# STM32L052C6T6 register map
File version: 1.0
STM32L052C6T6,STM32L052C6U6,STM32L052C8T3,STM32L052C8T6,STM32L052C8T7,STM32L052C8U3,STM32L052C8U6,STM32L052C8U7,STM32L052K6T6,STM32L052K6T7,STM32L052K6U6,STM32L052K6U7,STM32L052K8T3,STM32L052K8T6,STM32L052K8T7,STM32L052K8U3,STM32L052K8U6,STM32L052K8U7,STM32L052R6H6,STM32L052R6T6,STM32L052R8H6,STM32L052R8H7,STM32L052R8T6,STM32L052R8T7,STM32L052T6Y6,STM32L052T6Y7,STM32L052T8F3,STM32L052T8F6,STM32L052T8F7,STM32L052T8Y3,STM32L052T8Y6,STM32L052T8Y7,STM32L062C8U6,STM32L062K8T6,STM32L062K8U6,STM32L072CBT6,STM32L072CBU6,STM32L072CBY6,STM32L072CZE3,STM32L072CZE6,STM32L072CZE7,STM32L072CZT3,STM32L072CZT6,STM32L072CZT7,STM32L072CZU3,STM32L072CZU6,STM32L072CZU7,STM32L072CZY3,STM32L072CZY6,STM32L072CZY7,STM32L072KBT6,STM32L072KBT7,STM32L072KBU3,STM32L072KBU6,STM32L072KBU7,STM32L072KZT6,STM32L072KZT7,STM32L072KZU6,STM32L072KZU7,STM32L072RBH3,STM32L072RBH6,STM32L072RBH7,STM32L072RBI3,STM32L072RBI6,STM32L072RBI7,STM32L072RBT3,STM32L072RBT6,STM32L072RBT7,STM32L072RZH3,STM32L072RZH6,STM32L072RZH7,STM32L072RZI3,STM32L072RZI6,STM32L072RZI7,STM32L072RZT3,STM32L072RZT6,STM32L072RZT7,STM32L072V8I6,STM32L072V8T6,STM32L072VBI6,STM32L072VBT6,STM32L072VZI6,STM32L072VZT6,STM32L082CZU3,STM32L082CZU6,STM32L082CZU7,STM32L082CZY3,STM32L082CZY6,STM32L082CZY7,STM32L082KBT6,STM32L082KBU6,STM32L082KZT6,STM32L082KZU6
Registers are 32-bit, access not given, reset 0x0 unless marked. A register's access mark holds for its fields unless they carry their own. Offsets are from the block's base; lines under a group give offsets from that group; [hi:lo] are bit positions; {n}, {i} and the like mark numbered series; 'fields as' and 'values as' point back to an identical list; <NAME> marks a mode.

## Memory map
0x40000000 TIM2
0x40000400 TIM3
0x40001000 TIM6
0x40001400 TIM7
0x40002800 RTC
0x40002800 BKP
0x40002C00 WWDG
0x40003000 IWDG
0x40003800 SPI2
0x40004400 USART2
0x40004800 LPUART1
0x40004C00 USART4
0x40005000 USART5
0x40005400 I2C1
0x40005800 I2C2
0x40005C00 USBFS
0x40006C00 CRS
0x40007000 PWR
0x40007400 DAC12
0x40007800 I2C3
0x40007C00 LPTIM1
0x40010000 COMP
0x40010000 SYSCFG
0x40010400 EXTI
0x40010800 TIM21
0x40011400 TIM22
0x40011C00 FW
0x40012400 ADC1
0x40013000 SPI1
0x40013800 USART1
0x40015800 DBG
0x40020000 DMA1
0x40021000 RCC
0x40022000 FLASH
0x40023000 CRC
0x40024000 TSC
0x40025000 RNG
0x40026000 AES
0x50000000 GPIOA
0x50000400 GPIOB
0x50000800 GPIOC
0x50000C00 GPIOD
0x50001000 GPIOE
0x50001C00 GPIOH

## TIM2
Base 0x40000000
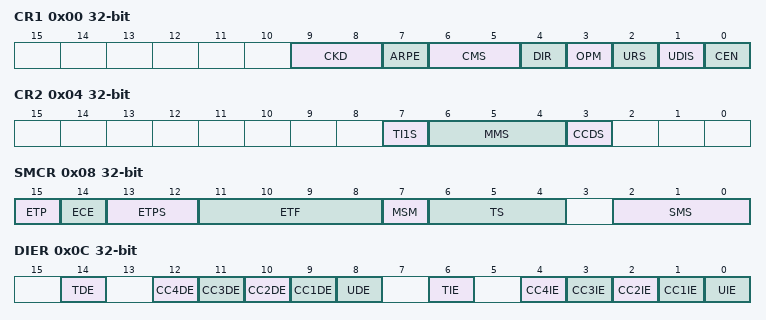
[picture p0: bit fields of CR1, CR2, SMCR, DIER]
0x00 CR1
  [9:8] CKD, [7] ARPE, [6:5] CMS, [4] DIR, [3] OPM, [2] URS, [1] UDIS, [0] CEN
0x04 CR2
  [7] TI1S, [6:4] MMS, [3] CCDS
0x08 SMCR
  [15] ETP, [14] ECE, [13:12] ETPS, [11:8] ETF, [7] MSM, [6:4] TS, [2:0] SMS
0x0C DIER
  [14] TDE, [n+8] CC{n}DE (n=1..4), [8] UDE, [6] TIE, [n] CC{n}IE (n=1..4), [0] UIE
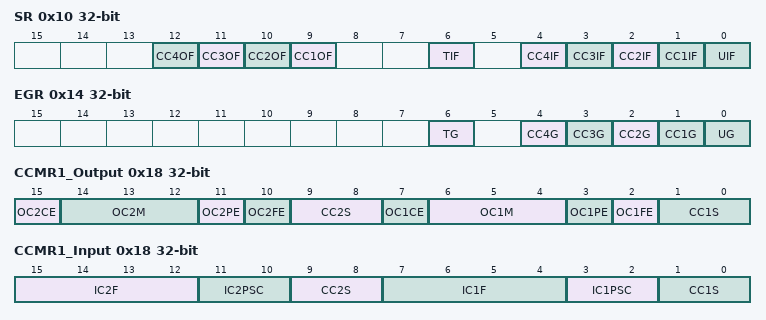
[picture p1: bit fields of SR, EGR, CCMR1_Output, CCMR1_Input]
0x10 SR
  [n+8] CC{n}OF (n=1..4), [6] TIF, [n] CC{n}IF (n=1..4), [0] UIF
0x14 EGR
  [6] TG, [n] CC{n}G (n=1..4), [0] UG
0x18 CCMR1_Output
  [15] OC2CE, [14:12] OC2M, [11] OC2PE, [10] OC2FE, [9:8] CC2S, [7] OC1CE, [6:4] OC1M, [3] OC1PE, [2] OC1FE, [1:0] CC1S
0x18 CCMR1_Input
  [15:12] IC2F, [11:10] IC2PSC, [9:8] CC2S, [7:4] IC1F, [3:2] IC1PSC, [1:0] CC1S
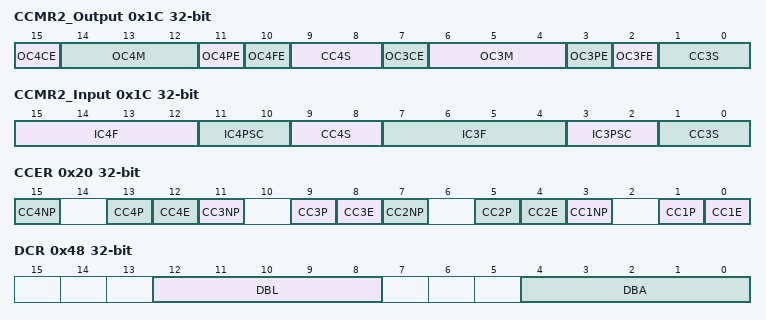
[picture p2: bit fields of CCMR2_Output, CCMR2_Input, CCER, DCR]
0x1C CCMR2_Output
  [15] OC4CE, [14:12] OC4M, [11] OC4PE, [10] OC4FE, [9:8] CC4S, [7] OC3CE, [6:4] OC3M, [3] OC3PE, [2] OC3FE, [1:0] CC3S
0x1C CCMR2_Input
  [15:12] IC4F, [11:10] IC4PSC, [9:8] CC4S, [7:4] IC3F, [3:2] IC3PSC, [1:0] CC3S
0x20 CCER
  [4n-1] CC{n}NP (n=1..4), [4n-3] CC{n}P (n=1..4), [4n-4] CC{n}E (n=1..4)
0x24 CNT
  [15:0] CNT
0x28 PSC
  [15:0] PSC
0x2C ARR
  [15:0] ARR
{0x30+4i} CCR{i} (i=1..4)
  [15:0] CCR{i}
0x48 DCR
  [12:8] DBL, [4:0] DBA
0x4C DMAR
  [15:0] DMAB
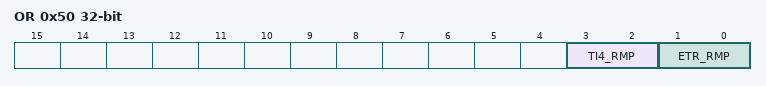
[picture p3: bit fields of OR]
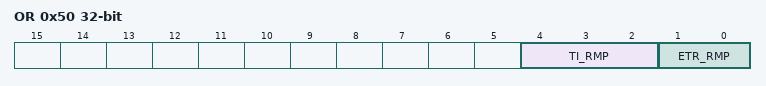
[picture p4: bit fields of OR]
0x50 OR
  [3:2] TI4_RMP, [1:0] ETR_RMP

## TIM3
Base 0x40000400
Registers as TIM2; these are added or differ:
0x50 OR
  [4:2] TI_RMP, [1:0] ETR_RMP

## TIM6
Base 0x40001000
Same registers: TIM7 0x40001400
0x00 CR1
0x04 CR2
0x0C DIER
0x10 SR
0x14 EGR
0x24 CNT
0x28 PSC
0x2C ARR

## RTC
Base 0x40002800
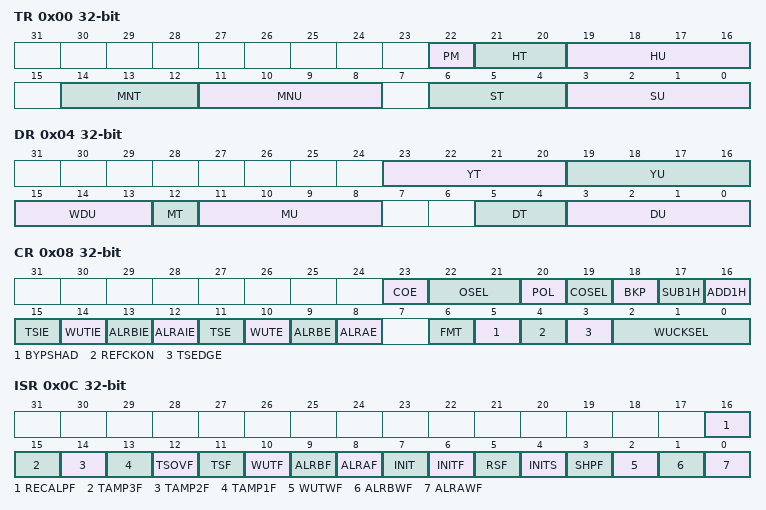
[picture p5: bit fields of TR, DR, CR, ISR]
0x00 TR
  [22] PM, [21:20] HT, [19:16] HU, [14:12] MNT, [11:8] MNU, [6:4] ST, [3:0] SU
0x04 DR
  [23:20] YT, [19:16] YU, [15:13] WDU, [12] MT, [11:8] MU, [5:4] DT, [3:0] DU
0x08 CR
  [23] COE, [22:21] OSEL, [20] POL, [19] COSEL, [18] BKP, [17] SUB1H, [16] ADD1H, [15] TSIE, [14] WUTIE, [13] ALRBIE, [12] ALRAIE, [11] TSE, [10] WUTE, [9] ALRBE, [8] ALRAE, [6] FMT, [5] BYPSHAD, [4] REFCKON, [3] TSEDGE, [2:0] WUCKSEL
0x0C ISR
  [16] RECALPF, [15] TAMP3F, [14] TAMP2F, [13] TAMP1F, [12] TSOVF, [11] TSF, [10] WUTF, [9] ALRBF, [8] ALRAF, [7] INIT, [6] INITF, [5] RSF, [4] INITS, [3] SHPF, [2] WUTWF, [1] ALRBWF, [0] ALRAWF
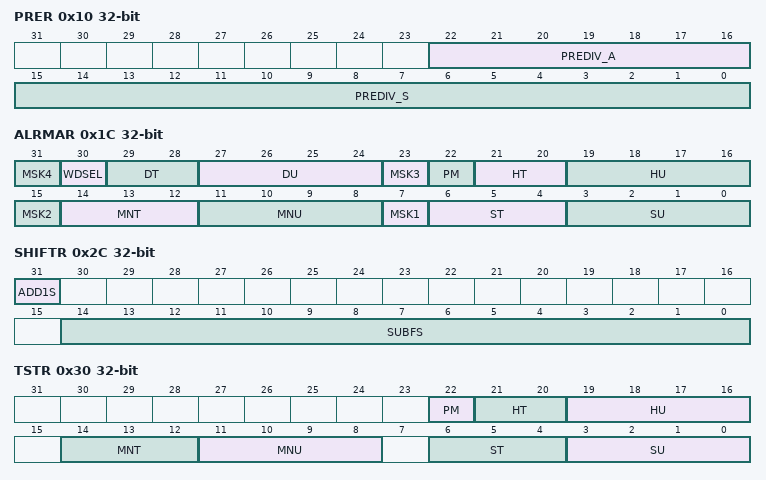
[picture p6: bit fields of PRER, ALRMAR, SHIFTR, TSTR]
0x10 PRER
  [22:16] PREDIV_A, [15:0] PREDIV_S
0x14 WUTR
  [15:0] WUT
0x1C ALRMAR
  [8n-1] MSK{n} (n=1..4), [30] WDSEL, [29:28] DT, [27:24] DU, [22] PM, [21:20] HT, [19:16] HU, [14:12] MNT, [11:8] MNU, [6:4] ST, [3:0] SU
0x20 ALRMBR
  [31] MSK4, [30] WDSEL, [29:28] DT, [27:24] DU, [23] MSK3, [22] PM, [21:20] HT, [19:16] HU, [14:12] MNT, [11:8] MNU, [15:7] MSK2, [6:4] ST, [3:0] SU
0x24 WPR
  [7:0] KEY
0x28 SSR
  [15:0] SS
0x2C SHIFTR
  [31] ADD1S, [14:0] SUBFS
0x30 TSTR
  fields as TR
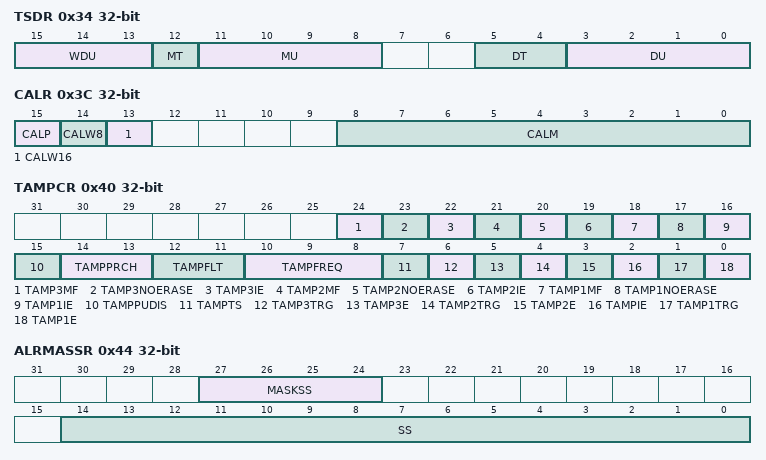
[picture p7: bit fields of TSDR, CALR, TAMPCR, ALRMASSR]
0x34 TSDR
  [15:13] WDU, [12] MT, [11:8] MU, [5:4] DT, [3:0] DU
0x38 TSSSR
  [15:0] SS
0x3C CALR
  [15] CALP, [14] CALW8, [13] CALW16, [8:0] CALM
0x40 TAMPCR
  [24] TAMP3MF, [23] TAMP3NOERASE, [22] TAMP3IE, [21] TAMP2MF, [20] TAMP2NOERASE, [19] TAMP2IE, [18] TAMP1MF, [17] TAMP1NOERASE, [16] TAMP1IE, [15] TAMPPUDIS, [14:13] TAMPPRCH, [12:11] TAMPFLT, [10:8] TAMPFREQ, [7] TAMPTS, [6] TAMP3TRG, [5] TAMP3E, [4] TAMP2TRG, [3] TAMP2E, [2] TAMPIE, [1] TAMP1TRG, [0] TAMP1E
0x44 ALRMASSR
  [27:24] MASKSS, [14:0] SS
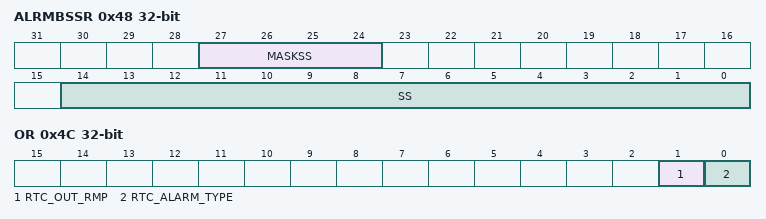
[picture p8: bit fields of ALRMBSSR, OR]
0x48 ALRMBSSR
  [27:24] MASKSS, [14:0] SS
0x4C OR
  [1] RTC_OUT_RMP, [0] RTC_ALARM_TYPE
{0x50+4i} BKP{i}R (i=0..4)
  [31:0] BKP

## BKP
Base 0x40002800
Registers as RTC; these are added or differ:
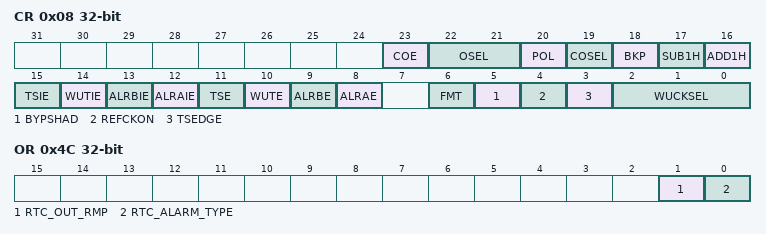
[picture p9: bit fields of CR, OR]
0x08 CR
  fields as RTC.CR
0x4C OR
  [1] RTC_OUT_RMP, [0] RTC_ALARM_TYPE
{0x50+4i} BKP{i}R (i=0..4)
  [31:0] BKP
